# LPC12D27 register map
File version: 3
Registers are 32-bit, read-write, reset 0x0 unless marked. A register's access mark holds for its fields unless they carry their own. Offsets are from the block's base; [hi:lo] are bit positions; {n}, {i} and the like mark numbered series.

## GPIO0 — Product name title=UM10441 Chapter title=LPC122x General Purpose I/O (GPIO) Modification date=2/11/2011 Major revision=0 Minor revision=17
Base 0x50000000
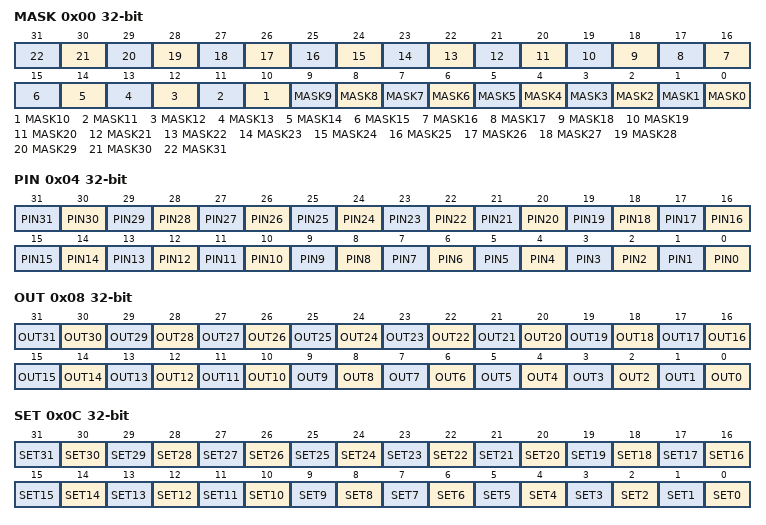
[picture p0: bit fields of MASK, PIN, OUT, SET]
0x00 MASK — Pin value mask register. Affects operations on PIN, OUT, SET, CLR, and NOT registers.
  [n] MASK{n} (n=0..31) — GPIO pin PIOn_x access control. 0 = read/write not masked. 1 = read/write masked.
0x04 PIN ro — Pin value register.
  [n] PIN{n} (n=0..31) — GPIO pin PIOn_x value. 0 = Digital pin level is LOW. 1 = Digital pin level is HIGH.
0x08 OUT — Pin output value register.
  [n] OUT{n} (n=0..31) — GPIO pin PIOn_x output value. 0 = Write: Set GPIO output pin to LOW. Read: GPIO output value is LOW. 1 = Write: Set GPIO output pin to HIGH. Read: GPIO output value is HIGH.
0x0C SET wo — Pin output value set register.
  [n] SET{n} (n=0..31) — Set GPIO pin PIOn_x output value. 0 = No effect on the GPIO output level. 1 = GPIO output is set to HIGH.
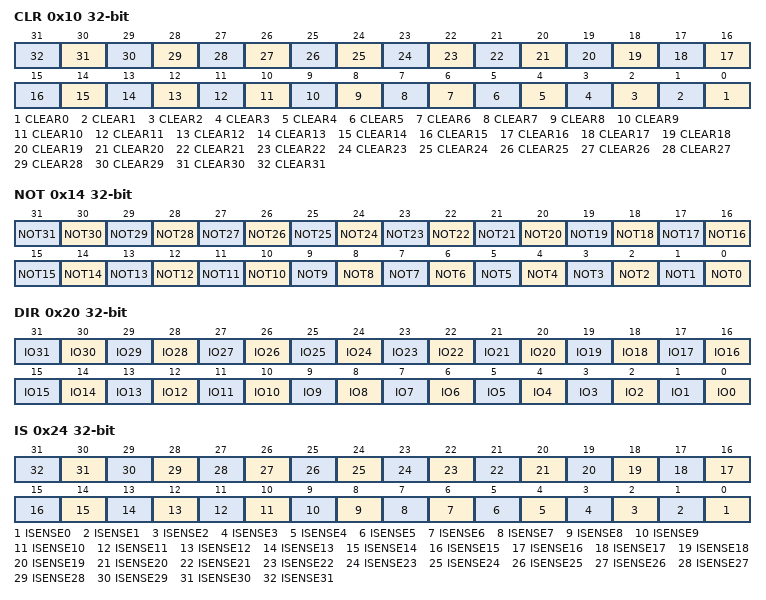
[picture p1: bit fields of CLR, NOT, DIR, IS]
0x10 CLR wo — Pin output value clear register.
  [n] CLEAR{n} (n=0..31) — Clear GPIO pin PIOn_x output value. 0 = No effect on the GPIO output level. 1 = GPIO output is set to LOW.
0x14 NOT wo — Pin output value invert register.
  [n] NOT{n} (n=0..31) — Invert GPIO pin PIOn_x output value. 0 = No effect on the GPIO output level. 1 = GPIO output is inverted from its current value.
0x20 DIR — Data direction register.
  [n] IO{n} (n=0..31) — Selects GPIO pin PIOn_x as input or output. 0 = Pin PIOn_x is configured as input. 1 = Pin PIOn_x is configured as output.
0x24 IS — Interrupt sense register.
  [n] ISENSE{n} (n=0..31) — Selects interrupt on pin PIOn_x as level or edge sensitive. 0 = Interrupt on pin PIOn_x is configured as edge sensitive. 1 = Interrupt on pin PIOn_x is configured as level sensitive.
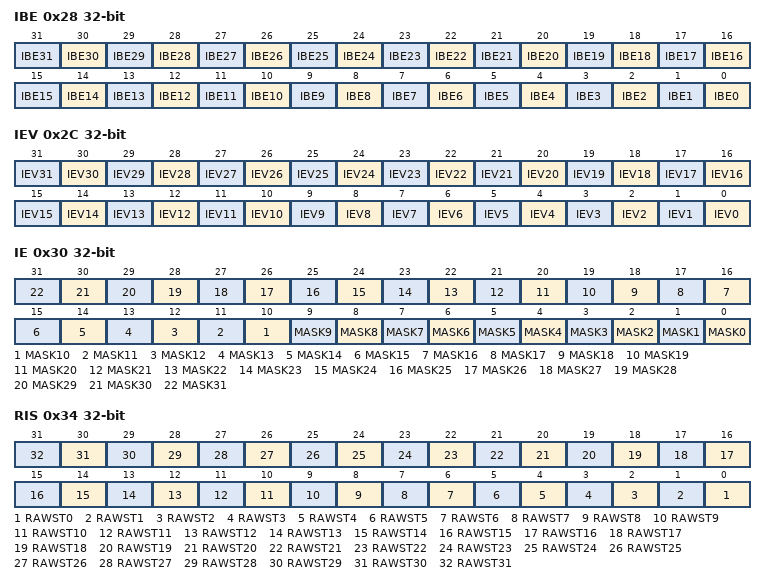
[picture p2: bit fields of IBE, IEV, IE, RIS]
0x28 IBE — Interrupt both edges register.
  [n] IBE{n} (n=0..31) — Selects interrupt on pin PIOn_x to be triggered on both edges. 0 = Interrupt on pin PIOn_x is controlled through register GPIOnIEV. 1 = Both edges on pin PIOn_x trigger an interrupt.
0x2C IEV — Interrupt event register.
  [n] IEV{n} (n=0..31) — Selects interrupt on pin PIOn_x to be triggered rising or falling edges. 0 = Depending on setting in register GPIOnIS, falling edges or LOW level on pin PIOn_x trigger an interrupt. 1 = Depending on setting in register GPIOnIS, rising edges or HIGH level on pin PIOn_x trigger an interrupt.
0x30 IE — Interrupt mask register.
  [n] MASK{n} (n=0..31) — Selects interrupt on pin PIOn_x to be masked. 0 = Interrupt on pin PIOn_x is masked. 1 = Interrupt on pin PIOn_x is not masked.
0x34 RIS ro — Raw interrupt status register.
  [n] RAWST{n} (n=0..31) — Raw interrupt status. 0 = No interrupt on pin PIOn_x. 1 = Interrupt requirements met on PIOn_x.
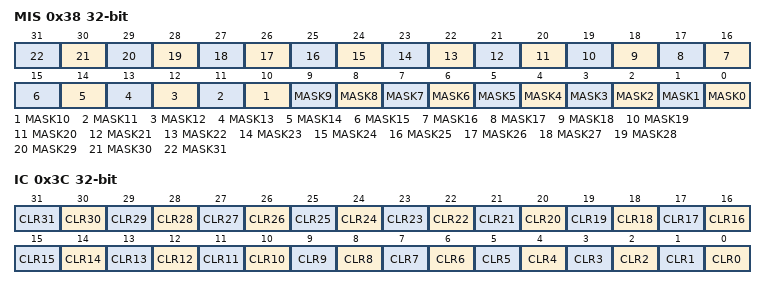
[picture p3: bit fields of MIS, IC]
0x38 MIS ro — Masked interrupt status register.
  [n] MASK{n} (n=0..31) — Selects interrupt on pin PIOn_x to be masked. 0 = No interrupt or interrupt masked on pin PIOn_x. 1 = Interrupt on PIOn_x.
0x3C IC wo — Interrupt clear register.
  [n] CLR{n} (n=0..31) — Selects interrupt on pin PIOn_x to be cleared. Clears the interrupt edge detection logic. 0 = No effect. 1 = Clears edge detection logic for pin PIOn_x.

## GPIO1 — Product name title=UM10441 Chapter title=LPC122x General Purpose I/O (GPIO) Modification date=2/11/2011 Major revision=0 Minor revision=17
Base 0x50010000
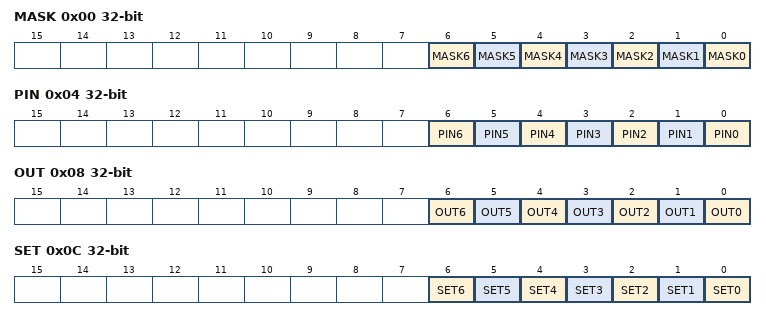
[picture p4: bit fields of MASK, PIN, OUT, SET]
0x00 MASK — Pin value mask register. Affects operations on PIN, OUT, SET, CLR, and NOT registers.
  [n] MASK{n} (n=0..6) — GPIO pin PIOn_x access control. 0 = read/write not masked. 1 = read/write masked.
0x04 PIN ro — Pin value register.
  [n] PIN{n} (n=0..6) — GPIO pin PIOn_x value. 0 = Digital pin level is LOW. 1 = Digital pin level is HIGH.
0x08 OUT — Pin output value register.
  [n] OUT{n} (n=0..6) — GPIO pin PIOn_x output value. 0 = Write: Set GPIO output pin to LOW. Read: GPIO output value is LOW. 1 = Write: Set GPIO output pin to HIGH. Read: GPIO output value is HIGH.
0x0C SET wo — Pin output value set register.
  [n] SET{n} (n=0..6) — Set GPIO pin PIOn_x output value. 0 = No effect on the GPIO output level. 1 = GPIO output is set to HIGH.
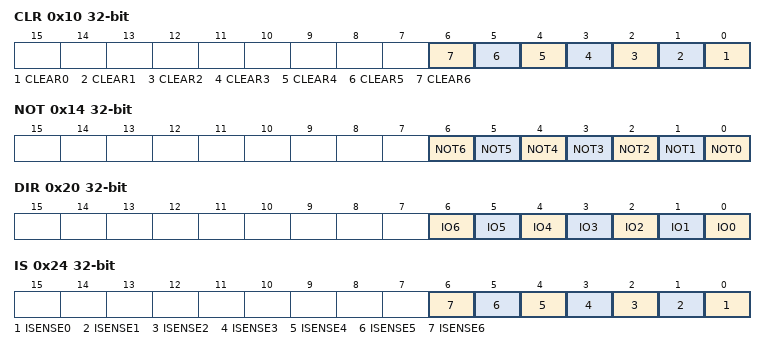
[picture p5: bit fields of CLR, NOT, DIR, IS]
0x10 CLR wo — Pin output value clear register.
  [n] CLEAR{n} (n=0..6) — Clear GPIO pin PIOn_x output value. 0 = No effect on the GPIO output level. 1 = GPIO output is set to LOW.
0x14 NOT wo — Pin output value invert register.
  [n] NOT{n} (n=0..6) — Invert GPIO pin PIOn_x output value. 0 = No effect on the GPIO output level. 1 = GPIO output is inverted from its current value.
0x20 DIR — Data direction register.
  [n] IO{n} (n=0..6) — Selects GPIO pin PIOn_x as input or output. 0 = Pin PIOn_x is configured as input. 1 = Pin PIOn_x is configured as output.
0x24 IS — Interrupt sense register.
  [n] ISENSE{n} (n=0..6) — Selects interrupt on pin PIOn_x as level or edge sensitive. 0 = Interrupt on pin PIOn_x is configured as edge sensitive. 1 = Interrupt on pin PIOn_x is configured as level sensitive.
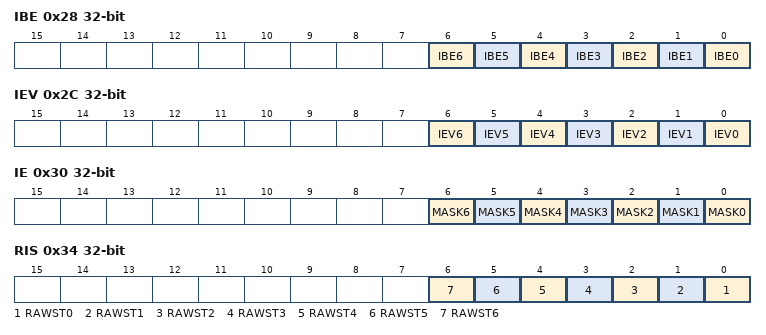
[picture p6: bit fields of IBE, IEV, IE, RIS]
0x28 IBE — Interrupt both edges register.
  [n] IBE{n} (n=0..6) — Selects interrupt on pin PIOn_x to be triggered on both edges. 0 = Interrupt on pin PIOn_x is controlled through register GPIOnIEV. 1 = Both edges on pin PIOn_x trigger an interrupt.
0x2C IEV — Interrupt event register.
  [n] IEV{n} (n=0..6) — Selects interrupt on pin PIOn_x to be triggered rising or falling edges. 0 = Depending on setting in register GPIOnIS, falling edges or LOW level on pin PIOn_x trigger an interrupt. 1 = Depending on setting in register GPIOnIS, rising edges or HIGH level on pin PIOn_x trigger an interrupt.
0x30 IE — Interrupt mask register.
  [n] MASK{n} (n=0..6) — Selects interrupt on pin PIOn_x to be masked. 0 = Interrupt on pin PIOn_x is masked. 1 = Interrupt on pin PIOn_x is not masked.
0x34 RIS ro — Raw interrupt status register.
  [n] RAWST{n} (n=0..6) — Raw interrupt status. 0 = No interrupt on pin PIOn_x. 1 = Interrupt requirements met on PIOn_x.
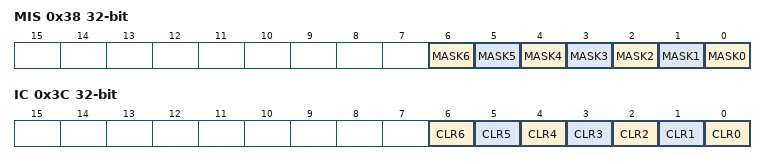
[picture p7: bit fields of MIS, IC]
0x38 MIS ro — Masked interrupt status register.
  [n] MASK{n} (n=0..6) — Selects interrupt on pin PIOn_x to be masked. 0 = No interrupt or interrupt masked on pin PIOn_x. 1 = Interrupt on PIOn_x.
0x3C IC wo — Interrupt clear register.
  [n] CLR{n} (n=0..6) — Selects interrupt on pin PIOn_x to be cleared. Clears the interrupt edge detection logic. 0 = No effect. 1 = Clears edge detection logic for pin PIOn_x.
